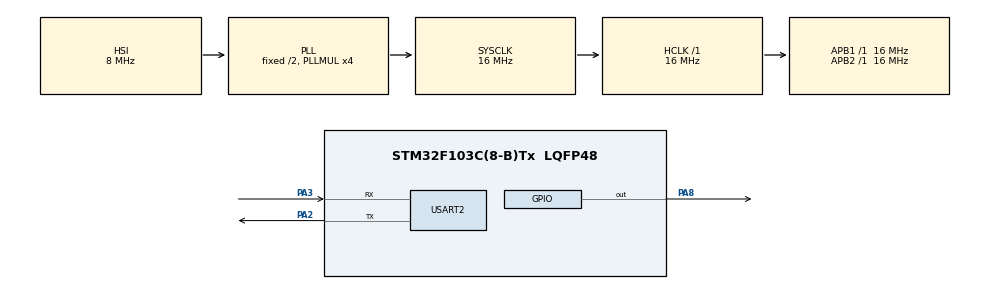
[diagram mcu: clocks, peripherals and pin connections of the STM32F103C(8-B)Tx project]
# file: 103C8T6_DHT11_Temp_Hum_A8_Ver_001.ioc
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Mcu.Family=STM32F1
Mcu.Name=STM32F103C(8-B)Tx
Mcu.Package=LQFP48
NVIC.PriorityGroup=NVIC_PRIORITYGROUP_4
PA13.Mode=Serial_Wire
PA13.Signal=SYS_JTMS-SWDIO
PA14.Mode=Serial_Wire
PA14.Signal=SYS_JTCK-SWCLK
PA2.Mode=Asynchronous
PA2.Signal=USART2_TX
PA3.Mode=Asynchronous
PA3.Signal=USART2_RX
PA8.Signal=GPIO_Output
PC14-OSC32_IN.Mode=LSE-External-Oscillator
PC14-OSC32_IN.Signal=RCC_OSC32_IN
PC15-OSC32_OUT.Mode=LSE-External-Oscillator
PC15-OSC32_OUT.Signal=RCC_OSC32_OUT
PD0-OSC_IN.Mode=HSE-External-Oscillator
PD0-OSC_IN.Signal=RCC_OSC_IN
PD1-OSC_OUT.Mode=HSE-External-Oscillator
PD1-OSC_OUT.Signal=RCC_OSC_OUT
ProjectManager.HeapSize=0x200
ProjectManager.StackSize=0x400
ProjectManager.TargetToolchain=STM32CubeIDE
RCC.AHBFreq_Value=16000000
RCC.APB1Freq_Value=16000000
RCC.APB1TimFreq_Value=16000000
RCC.APB2Freq_Value=16000000
RCC.APB2TimFreq_Value=16000000
RCC.HCLKFreq_Value=16000000
RCC.PLLMUL=RCC_PLL_MUL4
RCC.SYSCLKFreq_VALUE=16000000
RCC.SYSCLKSource=RCC_SYSCLKSOURCE_PLLCLK
RCC.USBFreq_Value=16000000
USART2.VirtualMode=VM_ASYNC
board=custom

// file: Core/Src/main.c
/* USER CODE BEGIN Header */
/**
 ******************************************************************************
 * @file           : main.c
 * @brief          : Main program body
 ******************************************************************************
 * @attention
 *
 * Copyright (c) 2025 STMicroelectronics.
 * All rights reserved.
 *
 * This software is licensed under terms that can be found in the LICENSE file
 * in the root directory of this software component.
 * If no LICENSE file comes with this software, it is provided AS-IS.
 *
 ******************************************************************************
 */
/* USER CODE END Header */
#include "main.h"

/* USER CODE BEGIN Includes */
#include <string.h>
#include <stdio.h>
/* USER CODE END Includes */

UART_HandleTypeDef huart2;

void SystemClock_Config(void);
static void MX_GPIO_Init(void);
static void MX_USART2_UART_Init(void);
/* USER CODE BEGIN PFP */
char msg[50];
uint8_t temperature = 0, humidity = 0;
uint8_t status;
/* USER CODE END PFP */

/* USER CODE BEGIN 0 */
void DWT_Init(void) {
	CoreDebug->DEMCR |= CoreDebug_DEMCR_TRCENA_Msk;
	DWT->CYCCNT = 0;
	DWT->CTRL |= DWT_CTRL_CYCCNTENA_Msk;
}

void DWT_Delay_us(uint32_t us) {
	uint32_t cycles = (SystemCoreClock / 1000000L) * us;
	uint32_t start = DWT->CYCCNT;
	while ((DWT->CYCCNT - start) < cycles)
		;
}
void DHT11_Pin_Output(void) {
	GPIO_InitTypeDef GPIO_InitStruct = { 0 };
	GPIO_InitStruct.Pin = GPIO_PIN_8;
	GPIO_InitStruct.Mode = GPIO_MODE_OUTPUT_OD;
	GPIO_InitStruct.Pull = GPIO_NOPULL;
	HAL_GPIO_Init(GPIOA, &GPIO_InitStruct);
}

void DHT11_Pin_Input(void) {
	GPIO_InitTypeDef GPIO_InitStruct = { 0 };
	GPIO_InitStruct.Pin = GPIO_PIN_8;
	GPIO_InitStruct.Mode = GPIO_MODE_INPUT;
	GPIO_InitStruct.Pull = GPIO_NOPULL;
	HAL_GPIO_Init(GPIOA, &GPIO_InitStruct);
}
uint8_t DHT11_Read(uint8_t *temp, uint8_t *humid) {
	uint8_t data[5] = { 0 };
	uint8_t i, j;

	// MCU start signal
	DHT11_Pin_Output();
	HAL_GPIO_WritePin(GPIOA, GPIO_PIN_8, GPIO_PIN_RESET);
	HAL_Delay(20);                  // ≥18 ms
	HAL_GPIO_WritePin(GPIOA, GPIO_PIN_8, GPIO_PIN_SET);
	DWT_Delay_us(30);

	// Now input mode
	DHT11_Pin_Input();

	DWT_Delay_us(80);
	if (HAL_GPIO_ReadPin(GPIOA, GPIO_PIN_8) != GPIO_PIN_RESET)
		return 1;
	DWT_Delay_us(80);
	if (HAL_GPIO_ReadPin(GPIOA, GPIO_PIN_8) != GPIO_PIN_SET)
		return 1;

	// Read 5 bytes
	for (j = 0; j < 5; j++) {
		for (i = 0; i < 8; i++) {
			while (HAL_GPIO_ReadPin(GPIOA, GPIO_PIN_8) == GPIO_PIN_RESET)
				;
			DWT_Delay_us(40);

			if (HAL_GPIO_ReadPin(GPIOA, GPIO_PIN_8) == GPIO_PIN_SET)
				data[j] |= (1 << (7 - i));

			while (HAL_GPIO_ReadPin(GPIOA, GPIO_PIN_8) == GPIO_PIN_SET)
				;
		}
	}

	// Checksum
	if (data[4] != (data[0] + data[1] + data[2] + data[3]))
		return 2;

	*humid = data[0];
	*temp = data[2];

	return 0;
}

/* USER CODE END 0 */

int main(void) {

	/* MCU Configuration--------------------------------------------------------*/

	/* Reset of all peripherals, Initializes the Flash interface and the Systick. */
	HAL_Init();

	/* Configure the system clock */
	SystemClock_Config();

	/* Initialize all configured peripherals */
	MX_GPIO_Init();
	MX_USART2_UART_Init();
	/* USER CODE BEGIN 2 */
	DWT_Init();
	sprintf(msg, "Status = %d\r\n", status);
	HAL_UART_Transmit(&huart2, (uint8_t*) msg, strlen(msg), 100);

	/* USER CODE END 2 */

	/* Infinite loop */
	while (1) {

		/* USER CODE BEGIN 3 */

		status = DHT11_Read(&temperature, &humidity);

		if (status == 0) {
			sprintf(msg, "Temp = %d C | Humidity = %d %%\r\n", temperature,
					humidity);
		} else {
			sprintf(msg, "DHT11 Error: %d\r\n", status);
		}

		HAL_UART_Transmit(&huart2, (uint8_t*) msg, strlen(msg), 100);

		HAL_Delay(2000);
	}
	/* USER CODE END 3 */
}

void SystemClock_Config(void) {
	RCC_OscInitTypeDef RCC_OscInitStruct = { 0 };
	RCC_ClkInitTypeDef RCC_ClkInitStruct = { 0 };

	/** Initializes the RCC Oscillators according to the specified parameters
	 * in the RCC_OscInitTypeDef structure.
	 */
	RCC_OscInitStruct.OscillatorType = RCC_OSCILLATORTYPE_HSI;
	RCC_OscInitStruct.HSIState = RCC_HSI_ON;
	RCC_OscInitStruct.HSICalibrationValue = RCC_HSICALIBRATION_DEFAULT;
	RCC_OscInitStruct.PLL.PLLState = RCC_PLL_ON;
	RCC_OscInitStruct.PLL.PLLSource = RCC_PLLSOURCE_HSI_DIV2;
	RCC_OscInitStruct.PLL.PLLMUL = RCC_PLL_MUL4;
	if (HAL_RCC_OscConfig(&RCC_OscInitStruct) != HAL_OK) {
		Error_Handler();
	}

	/** Initializes the CPU, AHB and APB buses clocks
	 */
	RCC_ClkInitStruct.ClockType = RCC_CLOCKTYPE_HCLK | RCC_CLOCKTYPE_SYSCLK
			| RCC_CLOCKTYPE_PCLK1 | RCC_CLOCKTYPE_PCLK2;
	RCC_ClkInitStruct.SYSCLKSource = RCC_SYSCLKSOURCE_PLLCLK;
	RCC_ClkInitStruct.AHBCLKDivider = RCC_SYSCLK_DIV1;
	RCC_ClkInitStruct.APB1CLKDivider = RCC_HCLK_DIV1;
	RCC_ClkInitStruct.APB2CLKDivider = RCC_HCLK_DIV1;

	if (HAL_RCC_ClockConfig(&RCC_ClkInitStruct, FLASH_LATENCY_0) != HAL_OK) {
		Error_Handler();
	}
}

static void MX_USART2_UART_Init(void) {

	huart2.Instance = USART2;
	huart2.Init.BaudRate = 115200;
	huart2.Init.WordLength = UART_WORDLENGTH_8B;
	huart2.Init.StopBits = UART_STOPBITS_1;
	huart2.Init.Parity = UART_PARITY_NONE;
	huart2.Init.Mode = UART_MODE_TX_RX;
	huart2.Init.HwFlowCtl = UART_HWCONTROL_NONE;
	huart2.Init.OverSampling = UART_OVERSAMPLING_16;
	if (HAL_UART_Init(&huart2) != HAL_OK) {
		Error_Handler();
	}

}

static void MX_GPIO_Init(void) {
	GPIO_InitTypeDef GPIO_InitStruct = { 0 };

	__HAL_RCC_GPIOA_CLK_ENABLE();
	__HAL_RCC_GPIOC_CLK_ENABLE();
	__HAL_RCC_GPIOD_CLK_ENABLE();

	/* PA8 for DHT11 */
	GPIO_InitStruct.Pin = GPIO_PIN_8;
	GPIO_InitStruct.Mode = GPIO_MODE_OUTPUT_OD;   // ✔ OPEN DRAIN
	GPIO_InitStruct.Pull = GPIO_NOPULL;
	GPIO_InitStruct.Speed = GPIO_SPEED_FREQ_LOW;
	HAL_GPIO_Init(GPIOA, &GPIO_InitStruct);

	HAL_GPIO_WritePin(GPIOA, GPIO_PIN_8, GPIO_PIN_SET);   // idle HIGH
}

void Error_Handler(void) {
	__disable_irq();
	while (1) {
	}
}
